# AVR128DA64S device description
Architecture: AVR8X; Family: AVR
Registers are 8-bit, read-write, reset 0x0 unless marked. A register's access mark holds for its fields unless they carry their own. Offsets are from the block's base; [hi:lo] are bit positions; {n}, {i} and the like mark numbered series; 'fields as' and 'values as' point back to an identical list.

## GPR — General Purpose Registers
Instances: GPR 0x001C
{0x0+i} GPR{i} reset not defined (i=0..3) — General Purpose Register {i}

## LOCK — Lockbits
Instances: LOCK 0x1040
0x00 KEY 32-bit reset 0x5CC5C55C — Lock Key Bits
  [31:0] KEY — Lock Key
    0x5CC5C55C=NOLOCK (No locks); 0xA33A3AA3=RWLOCK (Read and write lock)

## NVMCTRL — Non-volatile Memory Controller
Instances: NVMCTRL 0x1000
0x00 CTRLA — Control A
  [6:0] CMD — Command
    0=NONE (No Command); 1=NOOP (No Operation); 2=FLWR (Flash Write); 8=FLPER (Flash Page Erase); 9=FLMPER2 (Flash Multi-Page Erase 2 pages); 10=FLMPER4 (Flash Multi-Page Erase 4 pages); 11=FLMPER8 (Flash Multi-Page Erase 8 pages); 12=FLMPER16 (Flash Multi-Page Erase 16 pages); 13=FLMPER32 (Flash Multi-Page Erase 32 pages); 18=EEWR (EEPROM Write); 19=EEERWR (EEPROM Erase and Write); 24=EEBER (EEPROM Byte Erase); 25=EEMBER2 (EEPROM Multi-Byte Erase 2 bytes); 26=EEMBER4 (EEPROM Multi-Byte Erase 4 bytes); 27=EEMBER8 (EEPROM Multi-Byte Erase 8 bytes); 28=EEMBER16 (EEPROM Multi-Byte Erase 16 bytes); 29=EEMBER32 (EEPROM Multi-Byte Erase 32 bytes); 32=CHER (Chip Erase Command); 48=EECHER (EEPROM Erase Command)
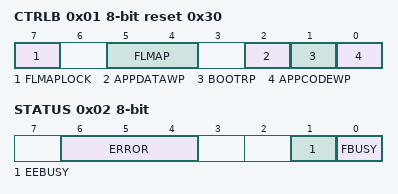
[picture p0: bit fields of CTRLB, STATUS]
0x01 CTRLB reset 0x30 — Control B
  [7] FLMAPLOCK — Flash Mapping Lock
  [5:4] FLMAP — Flash Mapping in Data space
    {v}=SECTION{v} (Flash section {v}) (v=0..3)
  [2] APPDATAWP — Application Data Write Protect
  [1] BOOTRP — Boot Read Protect
  [0] APPCODEWP — Application Code Write Protect
0x02 STATUS ro
  [6:4] ERROR — Write error
    0=NOERROR; 1=ILLEGALCMD (Write command not selected); 2=ILLEGALSADDR (Write to section not allowed); 3=DOUBLESELECT (Selecting new write command while write command already seleted); 4=ONGOINGPROG (Starting a new programming operation before previous is completed)
  [1] EEBUSY — EEPROM busy
  [0] FBUSY — Flash busy
0x03 INTCTRL — Interrupt Control
  [0] EEREADY — EEPROM Ready
0x04 INTFLAGS — Interrupt Flags
  [0] EEREADY — EEPROM Ready
0x06 DATA 16-bit reset not defined
0x08 ADDR 32-bit reset not defined — Address

## PORT — I/O Ports
Instances: PORTA 0x0400, PORTB 0x0420, PORTC 0x0440, PORTD 0x0460, PORTE 0x0480, PORTF 0x04A0, PORTG 0x04C0
0x00 DIR — Data Direction
0x01 DIRSET — Data Direction Set
0x02 DIRCLR — Data Direction Clear
0x03 DIRTGL — Data Direction Toggle
0x04 OUT — Output Value
0x05 OUTSET — Output Value Set
0x06 OUTCLR — Output Value Clear
0x07 OUTTGL — Output Value Toggle
0x08 IN — Input Value
0x09 INTFLAGS — Interrupt Flags
  [7:0] INT — Pin Interrupt Flag
0x0A PORTCTRL — Port Control
  [0] SRL — Slew Rate Limit Enable
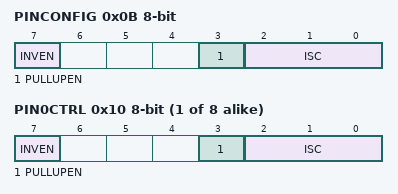
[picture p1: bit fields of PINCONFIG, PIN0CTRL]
0x0B PINCONFIG — Pin Control Config
  [7] INVEN — Inverted I/O Enable
  [3] PULLUPEN — Pullup enable
  [2:0] ISC — Input/Sense Configuration
    0=INTDISABLE (Interrupt disabled but input buffer enabled); 1=BOTHEDGES (Sense Both Edges); 2=RISING (Sense Rising Edge); 3=FALLING (Sense Falling Edge); 4=INPUT_DISABLE (Digital Input Buffer disabled); 5=LEVEL (Sense low Level)
0x0C PINCTRLUPD — Pin Control Update
  [7:0] PINCTRLUPD — Pin control update mask
0x0D PINCTRLSET — Pin Control Set
  [7:0] PINCTRLSET — Pin control set mask
0x0E PINCTRLCLR — Pin Control Clear
  [7:0] PINCTRLCLR — Pin control clear mask
{0x10+i} PIN{i}CTRL (i=0..7) — Pin {i} Control
  fields as PINCONFIG

## RSTCTRL — Reset controller
Instances: RSTCTRL 0x0040
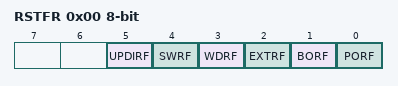
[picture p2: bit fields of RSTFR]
0x00 RSTFR — Reset Flags
  [5] UPDIRF — UPDI Reset flag
  [4] SWRF — Software Reset flag
  [3] WDRF — Watch dog Reset flag
  [2] EXTRF — External Reset flag
  [1] BORF — Brown out detector Reset flag
  [0] PORF — Power on Reset flag
0x01 SWRR — Software Reset
  [0] SWRST — Software reset enable

## RTC — Real-Time Counter
Instances: RTC 0x0140
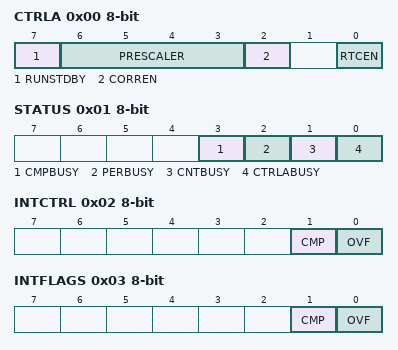
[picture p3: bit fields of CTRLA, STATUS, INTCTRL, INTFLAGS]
0x00 CTRLA — Control A
  [7] RUNSTDBY — Run In Standby
  [6:3] PRESCALER — Prescaling Factor
    0=DIV1 (RTC Clock / 1); 1=DIV2 (RTC Clock / 2); 2=DIV4 (RTC Clock / 4); 3=DIV8 (RTC Clock / 8); 4=DIV16 (RTC Clock / 16); 5=DIV32 (RTC Clock / 32); 6=DIV64 (RTC Clock / 64); 7=DIV128 (RTC Clock / 128); 8=DIV256 (RTC Clock / 256); 9=DIV512 (RTC Clock / 512); 10=DIV1024 (RTC Clock / 1024); 11=DIV2048 (RTC Clock / 2048); 12=DIV4096 (RTC Clock / 4096); 13=DIV8192 (RTC Clock / 8192); 14=DIV16384 (RTC Clock / 16384); 15=DIV32768 (RTC Clock / 32768)
  [2] CORREN — Correction enable
  [0] RTCEN — Enable
0x01 STATUS ro
  [3] CMPBUSY — Comparator Synchronization Busy Flag
  [2] PERBUSY — Period Synchronization Busy Flag
  [1] CNTBUSY — Count Synchronization Busy Flag
  [0] CTRLABUSY — CTRLA Synchronization Busy Flag
0x02 INTCTRL — Interrupt Control
  [1] CMP — Compare Match Interrupt enable
  [0] OVF — Overflow Interrupt enable
0x03 INTFLAGS — Interrupt Flags
  [1] CMP — Compare Match Interrupt
  [0] OVF — Overflow Interrupt Flag
0x04 TEMP reset not defined — Temporary
0x05 DBGCTRL — Debug control
  [0] DBGRUN — Run in debug
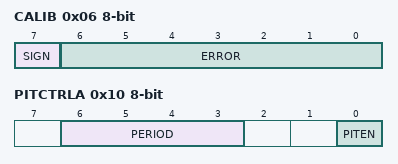
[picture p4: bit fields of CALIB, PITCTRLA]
0x06 CALIB — Calibration
  [7] SIGN — Error Correction Sign Bit
  [6:0] ERROR — Error Correction Value
0x07 CLKSEL — Clock Select
  [1:0] CLKSEL
    0=OSC32K (32.768 kHz from OSC32K); 1=OSC1K (1.024 kHz from OSC32K); 2=XOSC32K (32.768 kHz from XOSC32K); 3=EXTCLK (External Clock)
0x08 CNT 16-bit reset not defined — Counter
0x0A PER 16-bit reset 0xFFFF — Period
0x0C CMP 16-bit reset not defined — Compare
0x10 PITCTRLA — PIT Control A
  [6:3] PERIOD
    0=OFF; 1=CYC4 (RTC Clock Cycles 4); 2=CYC8 (RTC Clock Cycles 8); 3=CYC16 (RTC Clock Cycles 16); 4=CYC32 (RTC Clock Cycles 32); 5=CYC64 (RTC Clock Cycles 64); 6=CYC128 (RTC Clock Cycles 128); 7=CYC256 (RTC Clock Cycles 256); 8=CYC512 (RTC Clock Cycles 512); 9=CYC1024 (RTC Clock Cycles 1024); 10=CYC2048 (RTC Clock Cycles 2048); 11=CYC4096 (RTC Clock Cycles 4096); 12=CYC8192 (RTC Clock Cycles 8192); 13=CYC16384 (RTC Clock Cycles 16384); 14=CYC32768 (RTC Clock Cycles 32768)
  [0] PITEN — Enable
0x11 PITSTATUS ro
  [0] CTRLBUSY — CTRLA Synchronization Busy Flag
0x12 PITINTCTRL — PIT Interrupt Control
  [0] PI — Periodic Interrupt
0x13 PITINTFLAGS — PIT Interrupt Flags
  [0] PI — Periodic Interrupt
0x15 PITDBGCTRL — PIT Debug control
  [0] DBGRUN — Run in debug
